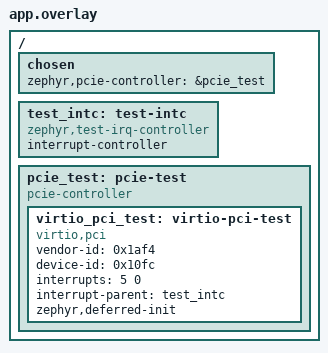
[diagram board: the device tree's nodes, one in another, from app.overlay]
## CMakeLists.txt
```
# SPDX-FileCopyrightText: Copyright The Zephyr Project Contributors
# SPDX-License-Identifier: Apache-2.0

cmake_minimum_required(VERSION 3.28.0)
find_package(Zephyr REQUIRED HINTS $ENV{ZEPHYR_BASE})
project(virtio_pci_write64_endianness)

target_include_directories(app PRIVATE
  ${ZEPHYR_BASE}/drivers/virtio
)

target_sources(app PRIVATE src/main.c)
```

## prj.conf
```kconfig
# SPDX-FileCopyrightText: Copyright The Zephyr Project Contributors
# SPDX-License-Identifier: Apache-2.0

CONFIG_ZTEST=y
CONFIG_VIRTIO=y
CONFIG_VIRTIO_PCI=y
CONFIG_VIRTIO_LOG_LEVEL_OFF=y
CONFIG_HEAP_MEM_POOL_SIZE=4096
```

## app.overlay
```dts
/*
 * SPDX-FileCopyrightText: Copyright The Zephyr Project Contributors
 *
 * SPDX-License-Identifier: Apache-2.0
 */

/ {
	chosen {
		zephyr,pcie-controller = &pcie_test;
	};

	test_intc: test-intc {
		compatible = "zephyr,test-irq-controller";
		interrupt-controller;
		#interrupt-cells = <2>;
	};

	pcie_test: pcie-test {
		compatible = "pcie-controller";
		#address-cells = <1>;
		#size-cells = <1>;

		virtio_pci_test: virtio-pci-test {
			compatible = "virtio,pci";
			vendor-id = <0x1af4>;
			device-id = <0x10fc>;
			interrupts = <5 0>;
			interrupt-parent = <&test_intc>;
			zephyr,deferred-init;
			status = "okay";
		};
	};
};
```

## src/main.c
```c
/*
 * SPDX-FileCopyrightText: Copyright The Zephyr Project Contributors
 *
 * SPDX-License-Identifier: Apache-2.0
 */

#include <stdint.h>

#include <zephyr/sys/byteorder.h>
#include <zephyr/ztest.h>

#include "virtio_pci_write64.h"

#define TEST_VALUE UINT64_C(0x0123456789abcdef)

ZTEST(virtio_pci_write64_endianness, test_64_bit_value_is_stored_as_little_endian_dwords)
{
	uint64_t storage = 0U;
	const uint8_t *bytes = (const uint8_t *)&storage;

	virtio_pci_write64(TEST_VALUE, &storage);

	zassert_equal(sys_get_le32(bytes), UINT32_C(0x89abcdef));
	zassert_equal(sys_get_le32(bytes + sizeof(uint32_t)), UINT32_C(0x01234567));
	zassert_equal(sys_get_le64(bytes), TEST_VALUE);
}

ZTEST_SUITE(virtio_pci_write64_endianness, NULL, NULL, NULL, NULL, NULL);
```
